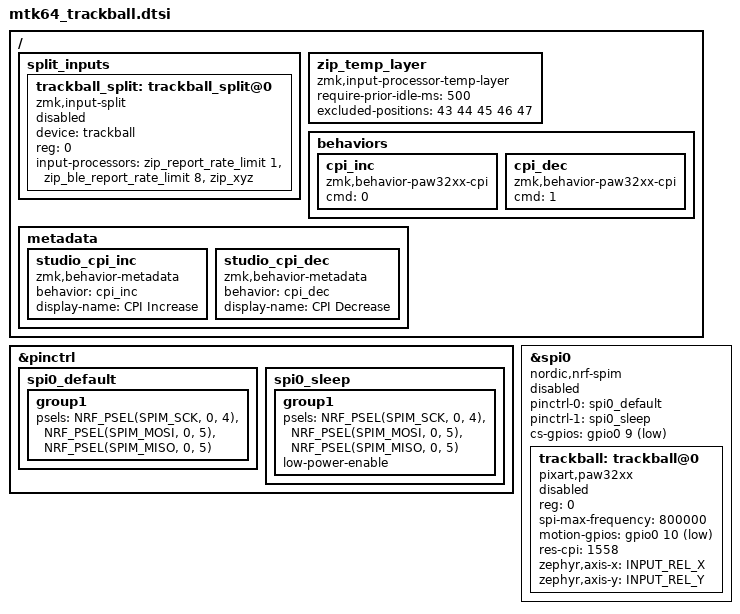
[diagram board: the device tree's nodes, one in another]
#include <zephyr/dt-bindings/input/input-event-codes.h>
#include <input/processors.dtsi>
#include <input/processors/xyz.dtsi>
#include <input/processors/report_rate_limit.dtsi>

&pinctrl {
    spi0_default: spi0_default {
        group1 {
            psels = <NRF_PSEL(SPIM_SCK, 0, 4)>,
                    <NRF_PSEL(SPIM_MOSI, 0, 5)>,
                    <NRF_PSEL(SPIM_MISO, 0, 5)>;
        };
    };

    spi0_sleep: spi0_sleep {
        group1 {
            psels = <NRF_PSEL(SPIM_SCK, 0, 4)>,
                    <NRF_PSEL(SPIM_MOSI, 0, 5)>,
                    <NRF_PSEL(SPIM_MISO, 0, 5)>;
            low-power-enable;
        };
    };
};

&spi0 {
    status = "disabled";
    compatible = "nordic,nrf-spim";
    pinctrl-0 = <&spi0_default>;
    pinctrl-1 = <&spi0_sleep>;
    pinctrl-names = "default", "sleep";
    cs-gpios = <&gpio0 9 GPIO_ACTIVE_LOW>;

    trackball: trackball@0 {
        status = "disabled";
        compatible = "pixart,paw32xx";
        reg = <0>;
        spi-max-frequency = <800000>;
        motion-gpios = <&gpio0 10 (GPIO_ACTIVE_LOW | GPIO_PULL_UP)>;
        res-cpi = <1558>;
        zephyr,axis-x = <INPUT_REL_X>;
        zephyr,axis-y = <INPUT_REL_Y>;
        // force-awake;
    };
};

/ {
    split_inputs {
        #address-cells = <1>;
        #size-cells = <0>;

        trackball_split: trackball_split@0 {
            status = "disabled";
            device = <&trackball>;
            compatible = "zmk,input-split";
            reg = <0>;
            input-processors = <&zip_report_rate_limit 1>, <&zip_ble_report_rate_limit 8>, <&zip_xyz>;
        };
    };

    zip_temp_layer: zip_temp_layer {
        compatible = "zmk,input-processor-temp-layer";
        #input-processor-cells = <2>;
        require-prior-idle-ms = <500>;
        excluded-positions = <43 44 45 46 47>; // MB4, MB5, MB1, MB2, MB3
    };

    behaviors {
        cpi_inc: cpi_inc {
            compatible = "zmk,behavior-paw32xx-cpi";
            #binding-cells = <0>;
            cmd = <0>;
        };

        cpi_dec: cpi_dec {
            compatible = "zmk,behavior-paw32xx-cpi";
            #binding-cells = <0>;
            cmd = <1>;
        };
    };

    metadata {
        studio_cpi_inc: studio_cpi_inc {
            compatible = "zmk,behavior-metadata";
            behavior = <&cpi_inc>;
            display-name = "CPI Increase";
        };

        studio_cpi_dec: studio_cpi_dec {
            compatible = "zmk,behavior-metadata";
            behavior = <&cpi_dec>;
            display-name = "CPI Decrease";
        };
    };
};
